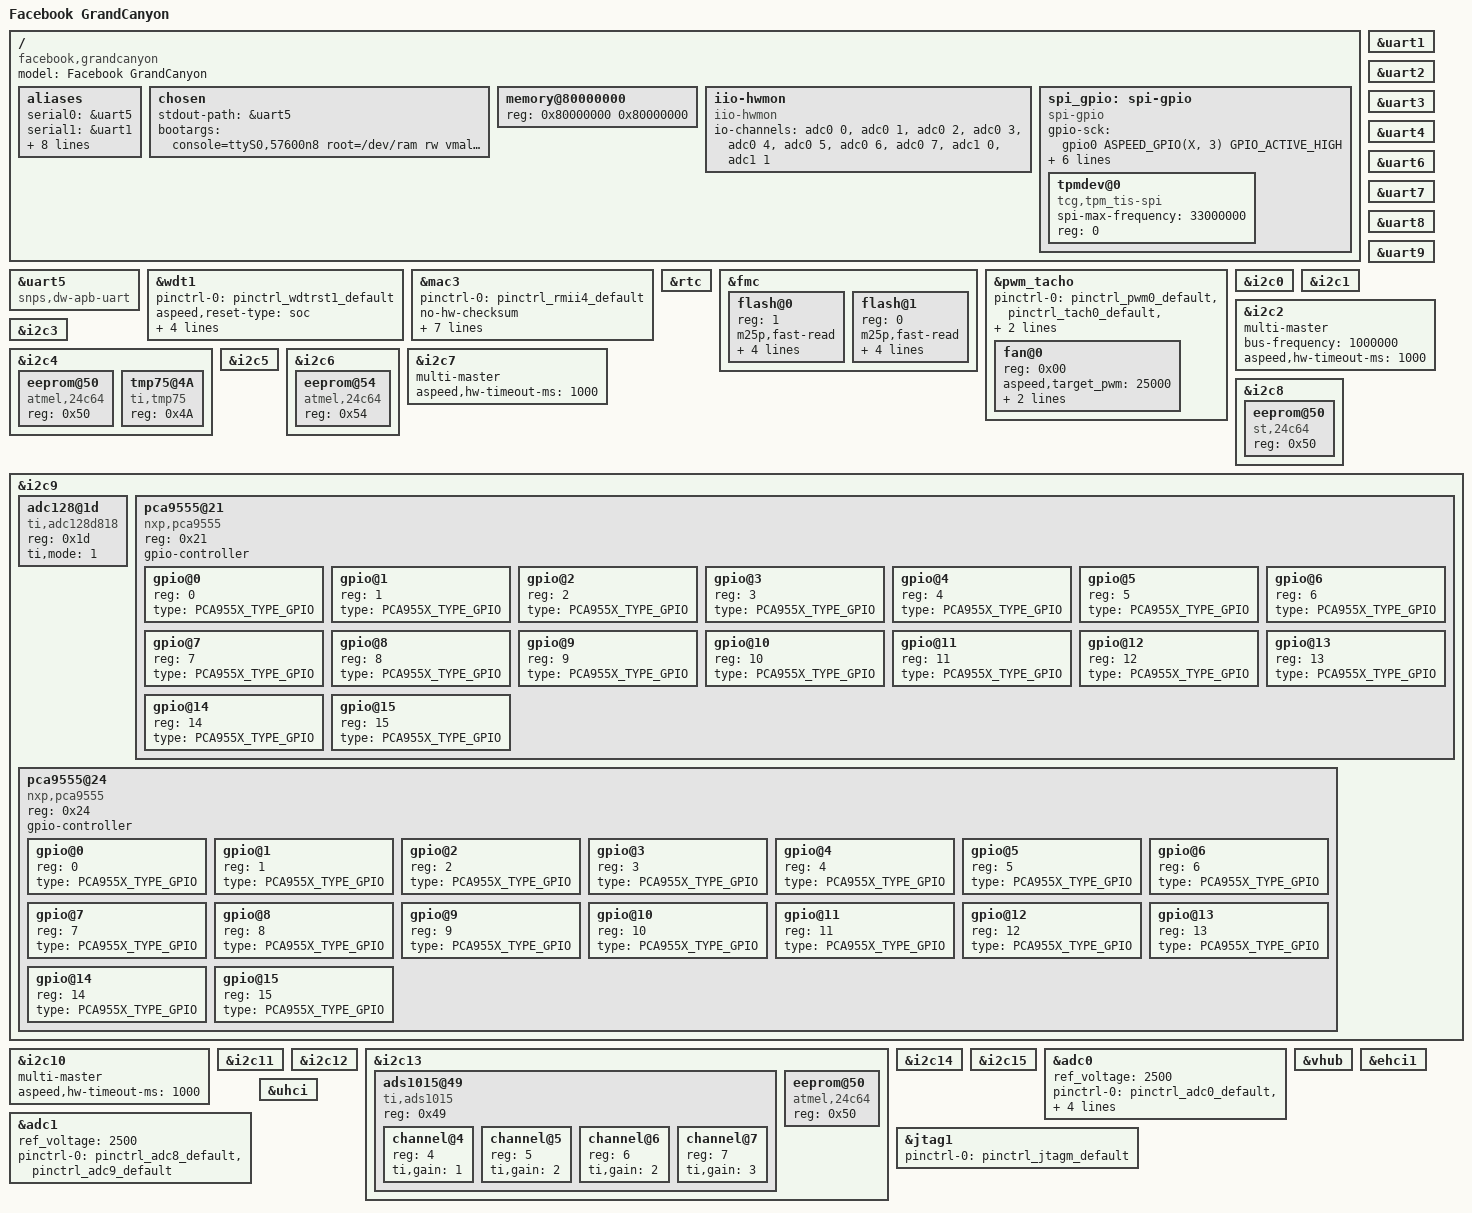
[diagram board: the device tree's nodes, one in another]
// SPDX-License-Identifier: GPL-2.0-or-later
// Copyright (c) 2020 Facebook Inc.

/dts-v1/;

#include "aspeed-g6.dtsi"
#include <dt-bindings/gpio/aspeed-gpio.h>
#include <dt-bindings/leds/leds-pca955x.h>

/ {
	model = "Facebook GrandCanyon";
	compatible = "facebook,grandcanyon", "aspeed,ast2600";

	aliases {
		serial0 = &uart5;
		serial1 = &uart1;
		serial2 = &uart2;
		serial3 = &uart3;
		serial4 = &uart4;
		serial5 = &uart6;
		serial6 = &uart7;
		serial7 = &uart8;
		serial8 = &uart9;

		spi2 = &spi_gpio;
	};

	chosen {
		stdout-path = &uart5;
		bootargs = "console=ttyS0,57600n8 root=/dev/ram rw vmalloc=384M";
	};

	memory@80000000 {
		device_type = "memory";
		reg = <0x80000000 0x80000000>;
	};
	iio-hwmon {
		compatible = "iio-hwmon";
		io-channels = <&adc0 0>, <&adc0 1>, <&adc0 2>, <&adc0 3>,
			<&adc0 4>, <&adc0 5>, <&adc0 6>, <&adc0 7>,
			<&adc1 0>, <&adc1 1>;
	};

	spi_gpio: spi-gpio {
		status = "okay";
		compatible = "spi-gpio";
		#address-cells = <1>;
		#size-cells = <0>;

		gpio-sck = <&gpio0 ASPEED_GPIO(X, 3) GPIO_ACTIVE_HIGH>;
		gpio-mosi = <&gpio0 ASPEED_GPIO(X, 4) GPIO_ACTIVE_HIGH>;
		gpio-miso = <&gpio0 ASPEED_GPIO(X, 5) GPIO_ACTIVE_HIGH>;
		num-chipselects = <1>;
		cs-gpios = <&gpio0 ASPEED_GPIO(X, 0) GPIO_ACTIVE_LOW>;

		tpmdev@0 {
			compatible = "tcg,tpm_tis-spi";
			spi-max-frequency = <33000000>;
			reg = <0>;
		};
	};
};

&uart1 {
	status = "okay";
};

&uart2 {
	status = "okay";
};

&uart3 {
	status = "okay";
};

&uart4 {
	status = "okay";
};

&uart5 {
	status = "okay";
	/* Workaround for AST2600 A0 */
	compatible = "snps,dw-apb-uart";
};

&uart6 {
	status = "okay";
};

&uart7 {
	status = "okay";
};

&uart8 {
	status = "okay";
};

&uart9 {
	status = "okay";
};

&wdt1 {
	status = "okay";
	pinctrl-names = "default";
	pinctrl-0 = <&pinctrl_wdtrst1_default>;
	aspeed,reset-type = "soc";
	aspeed,external-signal;
	aspeed,ext-push-pull;
	aspeed,ext-active-high;
	aspeed,ext-pulse-duration = <256>;
};

&mac3 {
	status = "okay";

	pinctrl-names = "default";
	pinctrl-0 = <&pinctrl_rmii4_default>;
	no-hw-checksum;
	use-ncsi;
	ncsi-ctrl,start-redo-probe;
	ncsi-ctrl,no-channel-monitor;
	ncsi-package = <1>;
	ncsi-channel = <1>;
	ncsi-rexmit = <1>;
	ncsi-timeout = <2>;
};

&rtc {
	status = "okay";
};

&fmc {
    status = "okay";
    flash@0 {
        reg = < 1 >;
        status = "okay";
        m25p,fast-read;
        label = "spi0.1";
        spi-max-frequency = <50000000>;
        spi-tx-bus-width = <1>;
        spi-rx-bus-width = <4>;
#include "facebook-bmc-vboot2-flash1-layout.dtsi"
    };
    flash@1 {
        reg = < 0 >;
        status = "okay";
        m25p,fast-read;
        label = "spi0.0";
        spi-max-frequency = <50000000>;
        spi-tx-bus-width = <1>;
        spi-rx-bus-width = <4>;
#include "facebook-bmc-vboot2-flash0-layout.dtsi"
    };
};

&pwm_tacho {
        status = "okay";
        pinctrl-names = "default";
        pinctrl-0 = <&pinctrl_pwm0_default  &pinctrl_tach0_default
                     &pinctrl_tach2_default &pinctrl_tach3_default
                     &pinctrl_tach4_default>;
        fan@0 {
                reg = <0x00>;
                aspeed,target_pwm = <25000>;
                aspeed,fan-tach-ch = /bits/ 8 <0x00 0x02 0x03 0x04>;
                aspeed,min_rpm = <30>;
        };
};

&i2c0 {
	status = "okay";
};

&i2c1 {
	status = "okay";
};

// To BIC
&i2c2 {
	status = "okay";
	multi-master;
	bus-frequency = <1000000>;
	aspeed,hw-timeout-ms = <1000>;
};

// To FPGA of Barton Springs
&i2c3 {
	status = "okay";
};

&i2c4 {
	status = "okay";
	// UIC FRU
	eeprom@50 {
		compatible = "atmel,24c64";
		reg = <0x50>;
	};
	// UIC temperature
	tmp75@4A {
		compatible = "ti,tmp75";
		reg = <0x4A>;
	};
};

// To FPGA of UIC (PFR)
&i2c5 {
	status = "okay";
};

&i2c6 {
	status = "okay";

	// BSM FRU
	eeprom@54 {
		compatible = "atmel,24c64";
		reg = <0x54>;
	};
};

// To debug card
&i2c7 {
	status = "okay";
	multi-master;
	aspeed,hw-timeout-ms = <1000>;
};

// To NIC
&i2c8 {
	status = "okay";
	// MEZZ EEPROM
	eeprom@50 {
		compatible = "st,24c64";
		reg = <0x50>;
	};
};

&i2c9 {
	status = "okay";

	// Voltage sensor for E1.S
	adc128@1d {
		compatible = "ti,adc128d818";
		reg = <0x1d>;
		ti,mode = /bits/ 8 <1>;
	};

	// I/O expender for E1.S/MISC
	pca9555@21 {
		compatible = "nxp,pca9555";
		reg = <0x21>;
		#address-cells = <1>;
		#size-cells = <0>;
		gpio-controller;
		#gpio-cells = <2>;

		// I2C_E1S_1_RST_N
		gpio@0 {
			reg = <0>;
			type = <PCA955X_TYPE_GPIO>;
		};
		// I2C_E1S_2_RST_N
		gpio@1 {
			reg = <1>;
			type = <PCA955X_TYPE_GPIO>;
		};
		// E1S_1_LED_ACT
		gpio@2 {
			reg = <2>;
			type = <PCA955X_TYPE_GPIO>;
		};
		// E1S_2_LED_ACT
		gpio@3 {
			reg = <3>;
			type = <PCA955X_TYPE_GPIO>;
		};
		// SCC_STBY_PWR_EN
		gpio@4 {
			reg = <4>;
			type = <PCA955X_TYPE_GPIO>;
		};
		// SCC_FULL_PWR_EN
		gpio@5 {
			reg = <5>;
			type = <PCA955X_TYPE_GPIO>;
		};
		// BMC_EXP_SOFT_RST_N
		gpio@6 {
			reg = <6>;
			type = <PCA955X_TYPE_GPIO>;
		};
		// UIC_COMP_BIC_RST_N
		gpio@7 {
			reg = <7>;
			type = <PCA955X_TYPE_GPIO>;
		};
		// E1S_1_3V3EFUSE_PGOOD
		gpio@8 {
			reg = <8>;
			type = <PCA955X_TYPE_GPIO>;
		};
		// E1S_2_3V3EFUSE_PGOOD
		gpio@9 {
			reg = <9>;
			type = <PCA955X_TYPE_GPIO>;
		};
		// P12V_NIC_FAULT_N
		gpio@10 {
			reg = <10>;
			type = <PCA955X_TYPE_GPIO>;
		};
		// P3V3_NIC_FAULT_N
		gpio@11 {
			reg = <11>;
			type = <PCA955X_TYPE_GPIO>;
		};
		// SCC_POR_RST_N
		gpio@12 {
			reg = <12>;
			type = <PCA955X_TYPE_GPIO>;
		};
		// IOC_T7_SYS_PGOOD
		gpio@13 {
			reg = <13>;
			type = <PCA955X_TYPE_GPIO>;
		};
		// BMC_COMP_BLED
		gpio@14 {
			reg = <14>;
			type = <PCA955X_TYPE_GPIO>;
		};
		// BMC_COMP_YLED
		gpio@15 {
			reg = <15>;
			type = <PCA955X_TYPE_GPIO>;
		};
	};

	// I/O expender for INSERT/PWRGD
	pca9555@24 {
		compatible = "nxp,pca9555";
		reg = <0x24>;
		#address-cells = <1>;
		#size-cells = <0>;
		gpio-controller;
		#gpio-cells = <2>;

		// COMP_PRSNT_N
		gpio@0 {
			reg = <0>;
			type = <PCA955X_TYPE_GPIO>;
		};
		// FAN_0_INS_N
		gpio@1 {
			reg = <1>;
			type = <PCA955X_TYPE_GPIO>;
		};
		// FAN_1_INS_N
		gpio@2 {
			reg = <2>;
			type = <PCA955X_TYPE_GPIO>;
		};
		// FAN_2_INS_N
		gpio@3 {
			reg = <3>;
			type = <PCA955X_TYPE_GPIO>;
		};
		// FAN_3_INS_N
		gpio@4 {
			reg = <4>;
			type = <PCA955X_TYPE_GPIO>;
		};
		// UIC_RMT_INS_N
		gpio@5 {
			reg = <5>;
			type = <PCA955X_TYPE_GPIO>;
		};
		// SCC_LOC_INS_N
		gpio@6 {
			reg = <6>;
			type = <PCA955X_TYPE_GPIO>;
		};
		// SCC_RMT_INS_N
		gpio@7 {
			reg = <7>;
			type = <PCA955X_TYPE_GPIO>;
		};
		// SCC_LOC_TYPE_0
		gpio@8 {
			reg = <8>;
			type = <PCA955X_TYPE_GPIO>;
		};
		// SCC_RMT_TYPE_0
		gpio@9 {
			reg = <9>;
			type = <PCA955X_TYPE_GPIO>;
		};
		// SCC_STBY_PGOOD
		gpio@10 {
			reg = <10>;
			type = <PCA955X_TYPE_GPIO>;
		};
		// SCC_FULL_PGOOD
		gpio@11 {
			reg = <11>;
			type = <PCA955X_TYPE_GPIO>;
		};
		// COMP_PGOOD
		gpio@12 {
			reg = <12>;
			type = <PCA955X_TYPE_GPIO>;
		};
		// DRAWER_CLOSED_N
		gpio@13 {
			reg = <13>;
			type = <PCA955X_TYPE_GPIO>;
		};
		// E1S_1_PRSNT_N
		gpio@14 {
			reg = <14>;
			type = <PCA955X_TYPE_GPIO>;
		};
		// E1S_2_PRSNT_N
		gpio@15 {
			reg = <15>;
			type = <PCA955X_TYPE_GPIO>;
		};
	};
};

// To expander
&i2c10 {
	multi-master;
	aspeed,hw-timeout-ms = <1000>;
	status = "okay";
};

// To IOC
&i2c11 {
	status = "okay";
};

// [T5]: To E1.S SSD_1 [T7]: To IOCM
&i2c12 {
	status = "okay";
};

// [T5]: To E1.S SSD_2 [T7]: To IOCM
&i2c13 {
	status = "okay";

	// Voltage sensor for IOCM
	ads1015@49 {
		compatible = "ti,ads1015";
		reg = <0x49>;
		#address-cells = <1>;
		#size-cells = <0>;
		// P3V3_STBY_SENSE
		channel@4 {
			reg = <4>;
			ti,gain = <1>; // FSR: 4096 (mV)
		};
		// P1V8_SENSE
		channel@5 {
			reg = <5>;
			ti,gain = <2>; // FSR: 2048 (mV)
		};
		// P1V5_SENSE
		channel@6 {
			reg = <6>;
			ti,gain = <2>; // FSR: 2048 (mV)
		};
		// P0V865_SENSE
		channel@7 {
			reg = <7>;
			ti,gain = <3>; // FSR: 1024 (mV)
		};
	};

	// IOCM FRU
	eeprom@50 {
		compatible = "atmel,24c64";
		reg = <0x50>;
	};
};

&i2c14 {
	status = "okay";
};

&i2c15 {
	status = "okay";
};

&adc0 {
	ref_voltage = <2500>;
	status = "okay";

	pinctrl-0 = <&pinctrl_adc0_default &pinctrl_adc1_default
		&pinctrl_adc2_default &pinctrl_adc3_default
		&pinctrl_adc4_default &pinctrl_adc5_default
		&pinctrl_adc6_default &pinctrl_adc7_default>;
};

&adc1 {
	ref_voltage = <2500>;
	status = "okay";

	pinctrl-0 = <&pinctrl_adc8_default &pinctrl_adc9_default>;
};

&jtag1 {
       status = "okay";
       pinctrl-names = "default";
       pinctrl-0 = <&pinctrl_jtagm_default>;
};

&vhub {
      status = "okay";
};

// connect to BIC
&ehci1 {
      status = "okay";
};

&uhci {
	status = "okay";
};
